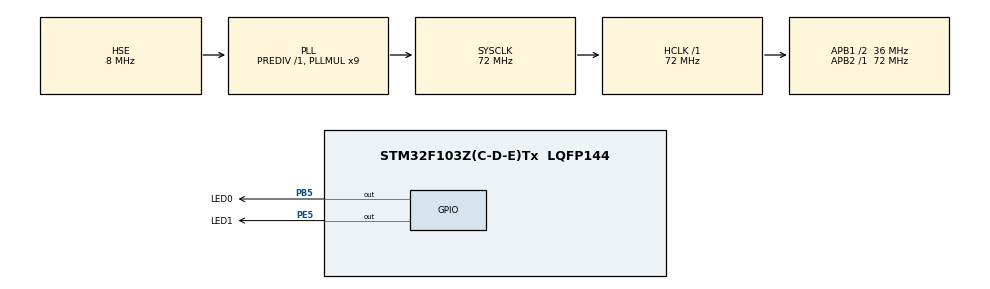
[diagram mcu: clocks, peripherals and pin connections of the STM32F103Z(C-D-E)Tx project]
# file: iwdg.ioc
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Mcu.Family=STM32F1
Mcu.Name=STM32F103Z(C-D-E)Tx
Mcu.Package=LQFP144
NVIC.PriorityGroup=NVIC_PRIORITYGROUP_4
OSC_IN.Mode=HSE-External-Oscillator
OSC_IN.Signal=RCC_OSC_IN
OSC_OUT.Mode=HSE-External-Oscillator
OSC_OUT.Signal=RCC_OSC_OUT
PA13.Mode=JTAG_4_pins
PA13.Signal=SYS_JTMS-SWDIO
PA14.Mode=JTAG_4_pins
PA14.Signal=SYS_JTCK-SWCLK
PA15.Mode=JTAG_4_pins
PA15.Signal=SYS_JTDI
PB3.Mode=JTAG_4_pins
PB3.Signal=SYS_JTDO-TRACESWO
PB5.GPIO_Label=LED0
PB5.GPIO_ModeDefaultOutputPP=GPIO_MODE_OUTPUT_PP
PB5.GPIO_PuPd=GPIO_PULLUP
PB5.GPIO_Speed=GPIO_SPEED_FREQ_HIGH
PB5.PinState=GPIO_PIN_SET
PB5.Signal=GPIO_Output
PC14-OSC32_IN.Mode=LSE-External-Oscillator
PC14-OSC32_IN.Signal=RCC_OSC32_IN
PC15-OSC32_OUT.Mode=LSE-External-Oscillator
PC15-OSC32_OUT.Signal=RCC_OSC32_OUT
PE5.GPIO_Label=LED1
PE5.GPIO_ModeDefaultOutputPP=GPIO_MODE_OUTPUT_PP
PE5.GPIO_PuPd=GPIO_PULLUP
PE5.GPIO_Speed=GPIO_SPEED_FREQ_HIGH
PE5.PinState=GPIO_PIN_SET
PE5.Signal=GPIO_Output
ProjectManager.HeapSize=0x200
ProjectManager.StackSize=0x400
ProjectManager.TargetToolchain=STM32CubeIDE
RCC.AHBFreq_Value=72000000
RCC.APB1CLKDivider=RCC_HCLK_DIV2
RCC.APB1Freq_Value=36000000
RCC.APB1TimFreq_Value=72000000
RCC.APB2Freq_Value=72000000
RCC.APB2TimFreq_Value=72000000
RCC.HCLKFreq_Value=72000000
RCC.PLLMUL=RCC_PLL_MUL9
RCC.PLLSourceVirtual=RCC_PLLSOURCE_HSE
RCC.RTCClockSelection=RCC_RTCCLKSOURCE_LSE
RCC.SYSCLKFreq_VALUE=72000000
RCC.SYSCLKSource=RCC_SYSCLKSOURCE_PLLCLK
RCC.USBFreq_Value=72000000
VP_IWDG_VS_IWDG.Mode=IWDG_Activate
VP_RTC_VS_RTC_Activate.Mode=RTC_Enabled
board=custom

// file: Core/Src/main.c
/* USER CODE BEGIN Header */
/**
  ******************************************************************************
  * @file           : main.c
  * @brief          : Main program body
  ******************************************************************************
  * @attention
  *
  * Copyright (c) 2022 STMicroelectronics.
  * All rights reserved.
  *
  * This software is licensed under terms that can be found in the LICENSE file
  * in the root directory of this software component.
  * If no LICENSE file comes with this software, it is provided AS-IS.
  *
  ******************************************************************************
  */
/* USER CODE END Header */
#include "main.h"

IWDG_HandleTypeDef hiwdg;
RTC_HandleTypeDef hrtc;

void SystemClock_Config(void);
static void MX_GPIO_Init(void);
static void MX_IWDG_Init(void);
static void MX_RTC_Init(void);

int main(void)
{

  /* MCU Configuration--------------------------------------------------------*/

  /* Reset of all peripherals, Initializes the Flash interface and the Systick. */
  HAL_Init();

  /* Configure the system clock */
  SystemClock_Config();

  /* Initialize all configured peripherals */
  MX_GPIO_Init();
  MX_IWDG_Init();
  MX_RTC_Init();
  /* USER CODE BEGIN 2 */
  //LED ON
  HAL_GPIO_WritePin(LED1_GPIO_Port, LED1_Pin, GPIO_PIN_RESET);
  HAL_GPIO_WritePin(LED0_GPIO_Port, LED0_Pin, GPIO_PIN_RESET);
  HAL_Delay(100);//100ms
  //LED OFF
  HAL_GPIO_WritePin(LED1_GPIO_Port, LED1_Pin, GPIO_PIN_SET);
  HAL_GPIO_WritePin(LED0_GPIO_Port, LED0_Pin, GPIO_PIN_SET);
  /* USER CODE END 2 */

  /* Infinite loop */
  while (1)
  {
	HAL_IWDG_Refresh(&hiwdg);
  }
}

void SystemClock_Config(void)
{
  RCC_OscInitTypeDef RCC_OscInitStruct = {0};
  RCC_ClkInitTypeDef RCC_ClkInitStruct = {0};
  RCC_PeriphCLKInitTypeDef PeriphClkInit = {0};

  /** Initializes the RCC Oscillators according to the specified parameters
  * in the RCC_OscInitTypeDef structure.
  */
  RCC_OscInitStruct.OscillatorType = RCC_OSCILLATORTYPE_LSI|RCC_OSCILLATORTYPE_HSE
                              |RCC_OSCILLATORTYPE_LSE;
  RCC_OscInitStruct.HSEState = RCC_HSE_ON;
  RCC_OscInitStruct.HSEPredivValue = RCC_HSE_PREDIV_DIV1;
  RCC_OscInitStruct.LSEState = RCC_LSE_ON;
  RCC_OscInitStruct.HSIState = RCC_HSI_ON;
  RCC_OscInitStruct.LSIState = RCC_LSI_ON;
  RCC_OscInitStruct.PLL.PLLState = RCC_PLL_ON;
  RCC_OscInitStruct.PLL.PLLSource = RCC_PLLSOURCE_HSE;
  RCC_OscInitStruct.PLL.PLLMUL = RCC_PLL_MUL9;
  if (HAL_RCC_OscConfig(&RCC_OscInitStruct) != HAL_OK)
  {
    Error_Handler();
  }

  /** Initializes the CPU, AHB and APB buses clocks
  */
  RCC_ClkInitStruct.ClockType = RCC_CLOCKTYPE_HCLK|RCC_CLOCKTYPE_SYSCLK
                              |RCC_CLOCKTYPE_PCLK1|RCC_CLOCKTYPE_PCLK2;
  RCC_ClkInitStruct.SYSCLKSource = RCC_SYSCLKSOURCE_PLLCLK;
  RCC_ClkInitStruct.AHBCLKDivider = RCC_SYSCLK_DIV1;
  RCC_ClkInitStruct.APB1CLKDivider = RCC_HCLK_DIV2;
  RCC_ClkInitStruct.APB2CLKDivider = RCC_HCLK_DIV1;

  if (HAL_RCC_ClockConfig(&RCC_ClkInitStruct, FLASH_LATENCY_2) != HAL_OK)
  {
    Error_Handler();
  }
  PeriphClkInit.PeriphClockSelection = RCC_PERIPHCLK_RTC;
  PeriphClkInit.RTCClockSelection = RCC_RTCCLKSOURCE_LSE;
  if (HAL_RCCEx_PeriphCLKConfig(&PeriphClkInit) != HAL_OK)
  {
    Error_Handler();
  }
}

static void MX_IWDG_Init(void)
{

  hiwdg.Instance = IWDG;
  hiwdg.Init.Prescaler = IWDG_PRESCALER_4;
  hiwdg.Init.Reload = 4095;
  if (HAL_IWDG_Init(&hiwdg) != HAL_OK)
  {
    Error_Handler();
  }

}

static void MX_RTC_Init(void)
{

  /** Initialize RTC Only
  */
  hrtc.Instance = RTC;
  hrtc.Init.AsynchPrediv = RTC_AUTO_1_SECOND;
  hrtc.Init.OutPut = RTC_OUTPUTSOURCE_ALARM;
  if (HAL_RTC_Init(&hrtc) != HAL_OK)
  {
    Error_Handler();
  }

}

static void MX_GPIO_Init(void)
{
  GPIO_InitTypeDef GPIO_InitStruct = {0};

  /* GPIO Ports Clock Enable */
  __HAL_RCC_GPIOE_CLK_ENABLE();
  __HAL_RCC_GPIOC_CLK_ENABLE();
  __HAL_RCC_GPIOA_CLK_ENABLE();
  __HAL_RCC_GPIOB_CLK_ENABLE();

  /*Configure GPIO pin Output Level */
  HAL_GPIO_WritePin(LED1_GPIO_Port, LED1_Pin, GPIO_PIN_SET);

  /*Configure GPIO pin Output Level */
  HAL_GPIO_WritePin(LED0_GPIO_Port, LED0_Pin, GPIO_PIN_SET);

  /*Configure GPIO pin : LED1_Pin */
  GPIO_InitStruct.Pin = LED1_Pin;
  GPIO_InitStruct.Mode = GPIO_MODE_OUTPUT_PP;
  GPIO_InitStruct.Pull = GPIO_PULLUP;
  GPIO_InitStruct.Speed = GPIO_SPEED_FREQ_HIGH;
  HAL_GPIO_Init(LED1_GPIO_Port, &GPIO_InitStruct);

  /*Configure GPIO pin : LED0_Pin */
  GPIO_InitStruct.Pin = LED0_Pin;
  GPIO_InitStruct.Mode = GPIO_MODE_OUTPUT_PP;
  GPIO_InitStruct.Pull = GPIO_PULLUP;
  GPIO_InitStruct.Speed = GPIO_SPEED_FREQ_HIGH;
  HAL_GPIO_Init(LED0_GPIO_Port, &GPIO_InitStruct);

}

void Error_Handler(void)
{
  __disable_irq();
  while (1)
  {
  }
}
